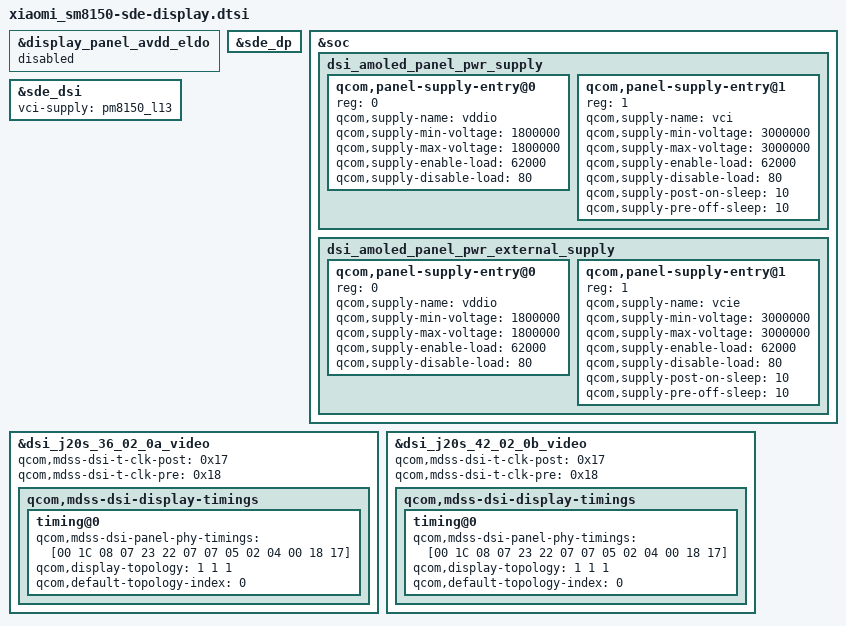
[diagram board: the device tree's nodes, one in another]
/* Copyright (c) 2016-2017, The Linux Foundation. All rights reserved.
 * Copyright (C) 2021 XiaoMi, Inc.
 *
 * This program is free software; you can redistribute it and/or modify
 * it under the terms of the GNU General Public License version 2 and
 * only version 2 as published by the Free Software Foundation.
 *
 * This program is distributed in the hope that it will be useful,
 * but WITHOUT ANY WARRANTY; without even the implied warranty of
 * MERCHANTABILITY or FITNESS FOR A PARTICULAR PURPOSE.  See the
 * GNU General Public License for more details.
 */

#include "../../qcom/sm8150-sde-display.dtsi"

#include "../vayu/display/dsi-panel-j20s-36-02-0a-lcd-dsc-vid.dtsi"
#include "../vayu/display/dsi-panel-j20s-42-02-0b-lcd-dsc-vid.dtsi"

&display_panel_avdd_eldo {
	status = "disabled";
};

&sde_dp {
	/delete-property/ qcom,dp-aux-switch;
};

&soc {
	dsi_amoled_panel_pwr_supply: dsi_amoled_panel_pwr_supply {
		#address-cells = <1>;
		#size-cells = <0>;

		qcom,panel-supply-entry@0 {
			reg = <0>;
			qcom,supply-name = "vddio";
			qcom,supply-min-voltage = <1800000>;
			qcom,supply-max-voltage = <1800000>;
			qcom,supply-enable-load = <62000>;
			qcom,supply-disable-load = <80>;
			// qcom,supply-post-on-sleep = <20>;
		};

		qcom,panel-supply-entry@1 {
			reg = <1>;
			qcom,supply-name = "vci";
			qcom,supply-min-voltage = <3000000>;
			qcom,supply-max-voltage = <3000000>;
			qcom,supply-enable-load = <62000>;
			qcom,supply-disable-load = <80>;
			qcom,supply-post-on-sleep = <10>;
			qcom,supply-pre-off-sleep = <10>;
		};
	};

	dsi_amoled_panel_pwr_external_supply: dsi_amoled_panel_pwr_external_supply {
		#address-cells = <1>;
		#size-cells = <0>;

		qcom,panel-supply-entry@0 {
			reg = <0>;
			qcom,supply-name = "vddio";
			qcom,supply-min-voltage = <1800000>;
			qcom,supply-max-voltage = <1800000>;
			qcom,supply-enable-load = <62000>;
			qcom,supply-disable-load = <80>;
			// qcom,supply-post-on-sleep = <20>;
		};

		qcom,panel-supply-entry@1 {
			reg = <1>;
			qcom,supply-name = "vcie";
			qcom,supply-min-voltage = <3000000>;
			qcom,supply-max-voltage = <3000000>;
			qcom,supply-enable-load = <62000>;
			qcom,supply-disable-load = <80>;
			qcom,supply-post-on-sleep = <10>;
			qcom,supply-pre-off-sleep = <10>;
		};
	};
};

&sde_dsi {
	/delete-property/ vdd-supply;
	vci-supply = <&pm8150_l13>;
};

&dsi_j20s_36_02_0a_video {
	qcom,mdss-dsi-t-clk-post = <0x17>;
	qcom,mdss-dsi-t-clk-pre = <0x18>;
	qcom,mdss-dsi-display-timings {
		/* 60 Hz */
		timing@0{
			qcom,mdss-dsi-panel-phy-timings = [00 1C 08 07 23 22 07
			07 05 02 04 00 18 17];
			qcom,display-topology = <1 1 1>;
			qcom,default-topology-index = <0>;
		};
	};
};

&dsi_j20s_42_02_0b_video {
	qcom,mdss-dsi-t-clk-post = <0x17>;
	qcom,mdss-dsi-t-clk-pre = <0x18>;
	qcom,mdss-dsi-display-timings {
		/* 120 Hz */
		timing@0{
			qcom,mdss-dsi-panel-phy-timings = [00 1C 08 07 23 22 07
			07 05 02 04 00 18 17];
			qcom,display-topology = <1 1 1>;
			qcom,default-topology-index = <0>;
		};
	};
};
